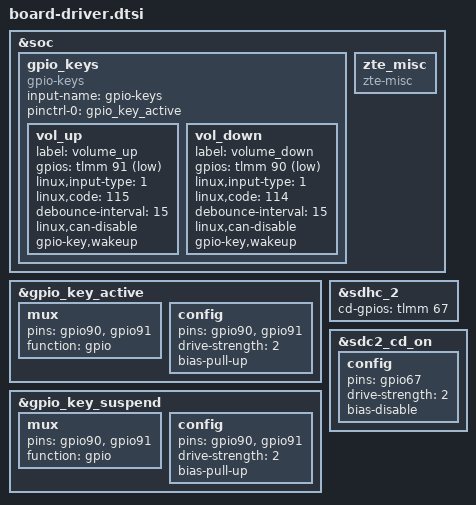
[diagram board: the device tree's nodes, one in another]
&soc {
	gpio_keys {
		compatible = "gpio-keys";
		input-name = "gpio-keys";
		pinctrl-names = "default";
		pinctrl-0 = <&gpio_key_active>;

		/delete-node/ camera_focus;
		/delete-node/ camera_snapshot;
		vol_up {
			label = "volume_up";
			gpios = <&tlmm 91 0x1>;
			linux,input-type = <1>;
			linux,code = <115>;
			debounce-interval = <15>;
			linux,can-disable;
			gpio-key,wakeup;
		};
		vol_down {
			label = "volume_down";
			gpios = <&tlmm 90 0x1>;
			linux,input-type = <1>;
			linux,code = <114>;
			debounce-interval = <15>;
			linux,can-disable;
			gpio-key,wakeup;
		};
	};

	zte_misc {
		compatible = "zte-misc";
	};
};
&gpio_key_active {
	mux {
		pins = "gpio90", "gpio91";
		function = "gpio";
	};
	config {
		pins = "gpio90", "gpio91";
		drive-strength = <2>;
		bias-pull-up;
	};
};
&gpio_key_suspend {
	mux {
		pins = "gpio90", "gpio91";
		function = "gpio";
	};
	config {
		pins = "gpio90", "gpio91";
		drive-strength = <2>;
		bias-pull-up;
	};
};


/*zteadd by wangxiaomei for SD cd pin start*/
&sdhc_2 {
	cd-gpios = <&tlmm 67 0x0>;
};
&sdc2_cd_on {
	config {
		pins = "gpio67";
		drive-strength = <2>;
		bias-disable;
	};
};
/*zteadd by wangxiaomei for SD cd pin end*/

